# ESP32S31_RADIO register map
Vendor: Espressif; Series: ESP32-S31; File version: 3.52
Registers are 32-bit, read-write, no defined reset value unless marked. A register's access mark holds for its fields unless they carry their own. Offsets are from the block's base; [hi:lo] are bit positions; lines under a group give offsets from that group.

## WIFI_MAC_CSI_DUMP — The CSI dump configuration word beside the RX descriptor walker, at the same base.
Base 0x20104000
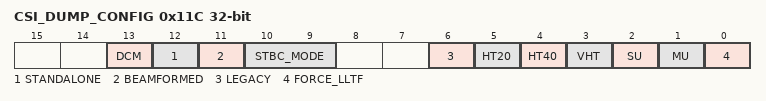
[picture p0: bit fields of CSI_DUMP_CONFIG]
0x11C CSI_DUMP_CONFIG — Project-assigned name. Complete esp_test_get_csi_dump_cfg reads every described field at 0x2010411c. Complete esp_test_set_csi_dump_cfg performs independent fresh-read RMW updates. Its BEAMFORMED update has a pinned vendor quirk: cfg[8] controls whether bit 11 is updated, but cfg[1] (MU) supplies the value. This SVD exposes the physical bit and does not reproduce that software bug.
  [13] DCM — Project-assigned name.
  [12] STANDALONE — Project-assigned name.
  [11] BEAMFORMED — Project-assigned name. Physical CSI-dump beamformed selector. The pinned vendor setter accidentally writes the MU argument when this field is selected; callers of the generated PAC write the actual bit directly.
  [10:9] STBC_MODE — Project-assigned name.
  [6] LEGACY — Project-assigned name.
  [5] HT20 — Project-assigned name.
  [4] HT40 — Project-assigned name.
  [3] VHT — Project-assigned name.
  [2] SU — Project-assigned name.
  [1] MU — Project-assigned name.
  [0] FORCE_LLTF — Project-assigned name.

## PHY_FECOEX_RECOVERED — Sparse FECOEX words absent from the public platform PAC.
Base 0x20100000
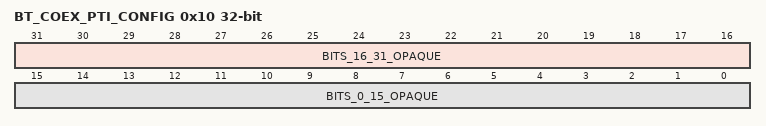
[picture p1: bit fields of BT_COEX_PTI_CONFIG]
0x10 BT_COEX_PTI_CONFIG — Project-assigned name. Complete coex_pti_v2 performs two ordered fresh-read RMW operations: it first replaces bits 31:16 with 0x0640, then replaces bits 15:0 with 0x0010. Individual bit meanings remain unknown.
  [31:16] BITS_16_31_OPAQUE — Opaque: meaning not established. Fixed 0x0640 image published by the first coex_pti_v2 RMW.
    on write: 0x640=REVIEWED_IMAGE (The only high-halfword image proved by coex_pti_v2.)
  [15:0] BITS_0_15_OPAQUE — Opaque: meaning not established. Fixed 0x0010 image published by the second coex_pti_v2 RMW.
    on write: 16=REVIEWED_IMAGE (The only low-halfword image proved by coex_pti_v2.)

## PHY_FEDATA_RECOVERED — Sparse FEDATA words absent from the public platform PAC.
Base 0x20100400
0x30 WORD_0030_OPAQUE — Opaque: meaning not established. Complete phy_rx_filter_mode performs a read-modify-write of FILTER_MODE; the other fields remain unnamed.
  [21:18] FILTER_MODE — Project-assigned name. Receive filter mode: complete phy_rx_filter_mode replaces these bits with the low four bits of its argument and preserves every other bit.
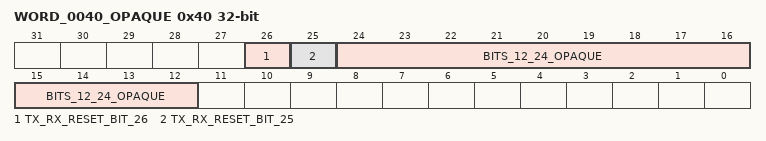
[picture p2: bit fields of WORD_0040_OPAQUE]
0x40 WORD_0040_OPAQUE — Opaque: meaning not established. Complete phy_fe_txrx_reset performs a read-modify-write; individual fields remain unnamed.
  [26] TX_RX_RESET_BIT_26 — Project-assigned name. Second upper reset bit cleared and then asserted by complete phy_fe_txrx_reset.
  [25] TX_RX_RESET_BIT_25 — Project-assigned name. First upper reset bit asserted by complete phy_fe_txrx_reset.
  [24:12] BITS_12_24_OPAQUE — Opaque: meaning not established. Thirteen-bit low reset group cleared by complete phy_fe_txrx_reset.

## PHY_FECTRL_RECOVERED — Sparse FECTRL antenna words absent from the public platform PAC.
Base 0x20100800
0x34 WORD_0034_OPAQUE — Opaque: meaning not established. Read-modify-written by complete antenna configuration functions and saved/restored by complete phy_dig_reg_backup.
0x38 WORD_0038_OPAQUE — Opaque: meaning not established. Read-modify-written by complete antenna configuration functions and saved/restored by complete phy_dig_reg_backup.
0x3C WORD_003C_OPAQUE — Opaque: meaning not established. Read-modify-written by complete antenna configuration functions and saved/restored by complete phy_dig_reg_backup.
0x40 WORD_0040_OPAQUE — Opaque: meaning not established. Read-modify-written by complete antenna configuration functions and saved/restored by complete phy_dig_reg_backup.
